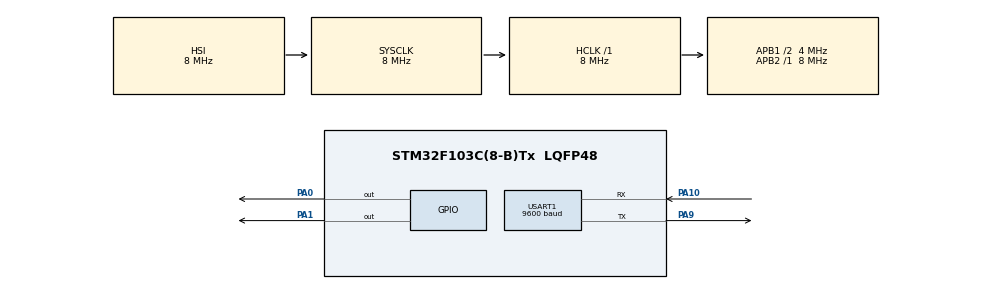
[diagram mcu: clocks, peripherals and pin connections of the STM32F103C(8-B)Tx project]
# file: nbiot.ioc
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Mcu.Family=STM32F1
Mcu.Name=STM32F103C(8-B)Tx
Mcu.Package=LQFP48
NVIC.PriorityGroup=NVIC_PRIORITYGROUP_4
NVIC.USART1_IRQn=true\:0\:0\:false\:false\:true\:true\:true
PA0-WKUP.Signal=GPIO_Output
PA1.Signal=GPIO_Output
PA10.Mode=Asynchronous
PA10.Signal=USART1_RX
PA13.Mode=Serial_Wire
PA13.Signal=SYS_JTMS-SWDIO
PA14.Mode=Serial_Wire
PA14.Signal=SYS_JTCK-SWCLK
PA9.Mode=Asynchronous
PA9.Signal=USART1_TX
ProjectManager.HeapSize=0x200
ProjectManager.StackSize=0x400
ProjectManager.TargetToolchain=MDK-ARM V5.32
RCC.AHBFreq_Value=8000000
RCC.APB1CLKDivider=RCC_HCLK_DIV2
RCC.APB1Freq_Value=4000000
RCC.APB1TimFreq_Value=8000000
RCC.APB2Freq_Value=8000000
RCC.APB2TimFreq_Value=8000000
RCC.HCLKFreq_Value=8000000
RCC.SYSCLKFreq_VALUE=8000000
RCC.USBFreq_Value=8000000
USART1.BaudRate=9600
USART1.VirtualMode=VM_ASYNC
board=custom

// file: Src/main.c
/* USER CODE BEGIN Header */
/**
  ******************************************************************************
  * @file           : main.c
  * @brief          : Main program body
  ******************************************************************************
  * @attention
  *
  * <h2><center>&copy; Copyright (c) 2024 STMicroelectronics.
  * All rights reserved.</center></h2>
  *
  * This software component is licensed by ST under BSD 3-Clause license,
  * the "License"; You may not use this file except in compliance with the
  * License. You may obtain a copy of the License at:
  *                        opensource.org/licenses/BSD-3-Clause
  *
  ******************************************************************************
  */
/* USER CODE END Header */
#include "main.h"
#include "usart.h"
#include "gpio.h"

/* USER CODE BEGIN Includes */
#include "nbiot.h"

/* USER CODE END Includes */

/* USER CODE BEGIN PTD */
char USART1_RxBuffer[RxBuffer_MaxSize];   //接收数据
uint8_t USART1_aRxBuffer;			//接收中断缓冲，用来一个字节一个字节接收
uint8_t UART1_Rx_Cnt = 0;		//接收缓冲计数
/* USER CODE END PTD */

void SystemClock_Config(void);

int main(void)
{

  /* MCU Configuration--------------------------------------------------------*/

  /* Reset of all peripherals, Initializes the Flash interface and the Systick. */
  HAL_Init();

  /* Configure the system clock */
  SystemClock_Config();

  /* Initialize all configured peripherals */
  MX_GPIO_Init();
  MX_USART1_UART_Init();
  /* USER CODE BEGIN 2 */
  HAL_GPIO_WritePin(GPIOA, GPIO_PIN_1, GPIO_PIN_SET);//拉高电平，启动NBIot

nbiot_reset();

NB_IotConnect();
NB_IoT_connect_MQTT();//连接到MQTT
  /* USER CODE END 2 */

  /* Infinite loop */
  while (1)
  {

  }
}

void SystemClock_Config(void)
{
  RCC_OscInitTypeDef RCC_OscInitStruct = {0};
  RCC_ClkInitTypeDef RCC_ClkInitStruct = {0};

  /** Initializes the RCC Oscillators according to the specified parameters
  * in the RCC_OscInitTypeDef structure.
  */
  RCC_OscInitStruct.OscillatorType = RCC_OSCILLATORTYPE_HSI;
  RCC_OscInitStruct.HSIState = RCC_HSI_ON;
  RCC_OscInitStruct.HSICalibrationValue = RCC_HSICALIBRATION_DEFAULT;
  RCC_OscInitStruct.PLL.PLLState = RCC_PLL_NONE;
  if (HAL_RCC_OscConfig(&RCC_OscInitStruct) != HAL_OK)
  {
    Error_Handler();
  }
  /** Initializes the CPU, AHB and APB buses clocks
  */
  RCC_ClkInitStruct.ClockType = RCC_CLOCKTYPE_HCLK|RCC_CLOCKTYPE_SYSCLK
                              |RCC_CLOCKTYPE_PCLK1|RCC_CLOCKTYPE_PCLK2;
  RCC_ClkInitStruct.SYSCLKSource = RCC_SYSCLKSOURCE_HSI;
  RCC_ClkInitStruct.AHBCLKDivider = RCC_SYSCLK_DIV1;
  RCC_ClkInitStruct.APB1CLKDivider = RCC_HCLK_DIV2;
  RCC_ClkInitStruct.APB2CLKDivider = RCC_HCLK_DIV1;

  if (HAL_RCC_ClockConfig(&RCC_ClkInitStruct, FLASH_LATENCY_0) != HAL_OK)
  {
    Error_Handler();
  }
}

/* USER CODE BEGIN 4 */
/* 串口接收中断回调函数 */
void HAL_UART_RxCpltCallback(UART_HandleTypeDef *huart)
{
if (huart->Instance == USART1)
	{
		USART1_RxBuffer[UART1_Rx_Cnt++] =USART1_aRxBuffer;   //接收数据转存
		if(USART1_RxBuffer[UART1_Rx_Cnt-1] == '\n'&& USART1_RxBuffer[UART1_Rx_Cnt-3] == 'K') //接收到OK时将接收标志位置0
			{
			UART1_Rx_Cnt = 0;
			}
		HAL_UART_Receive_IT(&huart1, (uint8_t *)&USART1_aRxBuffer, 1);   //再开启接收中断
	}
}
/* USER CODE END 4 */

void Error_Handler(void)
{
  __disable_irq();
  while (1)
  {
  }
}

/************************ (C) COPYRIGHT STMicroelectronics *****END OF FILE****/
